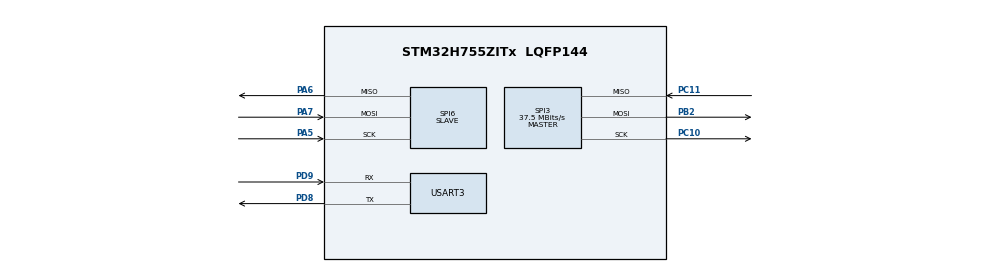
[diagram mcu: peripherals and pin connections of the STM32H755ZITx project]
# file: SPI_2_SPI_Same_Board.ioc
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CORTEX_M7.default_mode_Activation=1
CortexM4.IPs=BDMA,CORTEX_M4\:I,DMA,FATFS_M4\:I,FREERTOS_M4\:I,GPIO,IWDG2\:I,MDMA,NVIC2\:I,OPENAMP_M4\:I,PDM2PCM_M4\:I,PWR,RCC,RESMGR_UTILITY,SYS_M4\:I,USB_DEVICE_M4\:I,USB_HOST_M4\:I,VREFBUF,WWDG2\:I
CortexM7.IPs=BDMA\:I,CORTEX_M7\:I,DMA\:I,FATFS_M7\:I,FREERTOS_M7\:I,GPIO\:I,IWDG1\:I,MDMA\:I,NVIC1\:I,OPENAMP_M7\:I,PDM2PCM_M7\:I,PWR\:I,RCC\:I,RESMGR_UTILITY\:I,SYS\:I,USB_DEVICE_M7\:I,USB_HOST_M7\:I,VREFBUF\:I,WWDG1\:I,SPI3\:I,SPI6\:I,USART3\:I
Mcu.Family=STM32H7
Mcu.Name=STM32H755ZITx
Mcu.Package=LQFP144
NVIC1.PriorityGroup=NVIC_PRIORITYGROUP_4
NVIC2.PriorityGroup=NVIC_PRIORITYGROUP_4
PA5.Mode=Full_Duplex_Slave
PA5.PinAttribute=CortexM7
PA5.Signal=SPI6_SCK
PA6.Mode=Full_Duplex_Slave
PA6.PinAttribute=CortexM7
PA6.Signal=SPI6_MISO
PA7.Mode=Full_Duplex_Slave
PA7.PinAttribute=CortexM7
PA7.Signal=SPI6_MOSI
PB2.Mode=Full_Duplex_Master
PB2.PinAttribute=CortexM7
PB2.Signal=SPI3_MOSI
PC10.Mode=Full_Duplex_Master
PC10.PinAttribute=CortexM7
PC10.Signal=SPI3_SCK
PC11.Mode=Full_Duplex_Master
PC11.PinAttribute=CortexM7
PC11.Signal=SPI3_MISO
PD8.Mode=Asynchronous
PD8.PinAttribute=CortexM7
PD8.Signal=USART3_TX
PD9.Mode=Asynchronous
PD9.PinAttribute=CortexM7
PD9.Signal=USART3_RX
PH0-OSC_IN\ (PH0).Mode=HSE-External-Oscillator
PH0-OSC_IN\ (PH0).PinAttribute=Free
PH0-OSC_IN\ (PH0).Signal=RCC_OSC_IN
PH1-OSC_OUT\ (PH1).Mode=HSE-External-Oscillator
PH1-OSC_OUT\ (PH1).PinAttribute=Free
PH1-OSC_OUT\ (PH1).Signal=RCC_OSC_OUT
ProjectManager.HeapSize=M4-0x200,M7-0x200
ProjectManager.StackSize=M4-0x400,M7-0x400
ProjectManager.TargetToolchain=STM32CubeIDE
RCC.ADCFreq_Value=400000000
RCC.APB1Freq_Value=75000000
RCC.APB2Freq_Value=75000000
RCC.APB3Freq_Value=75000000
RCC.APB4Freq_Value=37500000
RCC.CortexFreq_Value=75000000
RCC.D3PPRE=RCC_APB4_DIV2
RCC.DIVM1=2
RCC.DIVM2=2
RCC.DIVN1=12
RCC.DIVN2=64
RCC.DIVQ2=25
RCC.HCLKFreq_Value=75000000
RCC.PLL2FRACN=0
RCC.PLLFRACN=0
RCC.PLLSourceVirtual=RCC_PLLSOURCE_HSE
RCC.SYSCLKFreq_VALUE=75000000
RCC.SYSCLKSource=RCC_SYSCLKSOURCE_PLLCLK
RCC.USART234578CLockSelection=RCC_USART234578CLKSOURCE_PLL2
RCC.USBFreq_Value=75000000
SPI3.CalculateBaudRate=37.5 MBits/s
SPI3.DataSize=SPI_DATASIZE_8BIT
SPI3.Direction=SPI_DIRECTION_2LINES
SPI3.Mode=SPI_MODE_MASTER
SPI3.VirtualType=VM_MASTER
SPI6.DataSize=SPI_DATASIZE_8BIT
SPI6.Direction=SPI_DIRECTION_2LINES
SPI6.Mode=SPI_MODE_SLAVE
SPI6.VirtualType=VM_SLAVE
SYS.userName=SYS_M7
USART3.VirtualMode-Asynchronous=VM_ASYNC
VP_SYS_M4_VS_Systick.Mode=SysTick
board=custom

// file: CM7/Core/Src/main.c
/* USER CODE BEGIN Header */
/**
  ******************************************************************************
  * @file           : main.c
  * @brief          : Main program body
  ******************************************************************************
  * @attention
  *
  * Copyright (c) 2024 STMicroelectronics.
  * All rights reserved.
  *
  * This software is licensed under terms that can be found in the LICENSE file
  * in the root directory of this software component.
  * If no LICENSE file comes with this software, it is provided AS-IS.
  *
  ******************************************************************************
  */
/* USER CODE END Header */
#include "main.h"
#include "spi.h"
#include "usart.h"
#include "gpio.h"

/* USER CODE BEGIN PD */

#ifndef HSEM_ID_0
#define HSEM_ID_0 (0U) /* HW semaphore 0*/
#endif

/* USER CODE END PD */

void SystemClock_Config(void);
static void MPU_Config(void);

int main(void)
{

/* USER CODE BEGIN Boot_Mode_Sequence_0 */
  int32_t timeout;
/* USER CODE END Boot_Mode_Sequence_0 */

  /* MPU Configuration--------------------------------------------------------*/
  MPU_Config();

/* USER CODE BEGIN Boot_Mode_Sequence_1 */
  /* Wait until CPU2 boots and enters in stop mode or timeout*/
  timeout = 0xFFFF;
  while((__HAL_RCC_GET_FLAG(RCC_FLAG_D2CKRDY) != RESET) && (timeout-- > 0));
  if ( timeout < 0 )
  {
  Error_Handler();
  }
/* USER CODE END Boot_Mode_Sequence_1 */
  /* MCU Configuration--------------------------------------------------------*/

  /* Reset of all peripherals, Initializes the Flash interface and the Systick. */
  HAL_Init();

  /* Configure the system clock */
  SystemClock_Config();
/* USER CODE BEGIN Boot_Mode_Sequence_2 */
/* When system initialization is finished, Cortex-M7 will release Cortex-M4 by means of
HSEM notification */
/*HW semaphore Clock enable*/
__HAL_RCC_HSEM_CLK_ENABLE();
/*Take HSEM */
HAL_HSEM_FastTake(HSEM_ID_0);
/*Release HSEM in order to notify the CPU2(CM4)*/
HAL_HSEM_Release(HSEM_ID_0,0);
/* wait until CPU2 wakes up from stop mode */
timeout = 0xFFFF;
while((__HAL_RCC_GET_FLAG(RCC_FLAG_D2CKRDY) == RESET) && (timeout-- > 0));
if ( timeout < 0 )
{
Error_Handler();
}
/* USER CODE END Boot_Mode_Sequence_2 */

  /* Initialize all configured peripherals */
  MX_GPIO_Init();
  MX_SPI3_Init();
  MX_SPI6_Init();
  MX_USART3_UART_Init();
  /* USER CODE BEGIN 2 */

  // Master sends data
  uint8_t dataToSend = 0x55;
  //HAL_SPI_Transmit(&hspi3, &dataToSend, 1, HAL_MAX_DELAY);

  // Master receives data
  uint8_t dataReceived;
  //HAL_SPI_Receive(&hspi6, &dataReceived, 1, HAL_MAX_DELAY);
  /* USER CODE END 2 */

  /* Infinite loop */
  while (1)
  {

    /* USER CODE BEGIN 3 */
	  HAL_SPI_Transmit(&hspi3, &dataToSend, 1, HAL_MAX_DELAY);
	  HAL_SPI_Receive(&hspi6, &dataReceived, 1, HAL_MAX_DELAY);
	  HAL_UART_Transmit(&huart3, &dataReceived, 1, HAL_MAX_DELAY);
  }
  /* USER CODE END 3 */
}

void SystemClock_Config(void)
{
  RCC_OscInitTypeDef RCC_OscInitStruct = {0};
  RCC_ClkInitTypeDef RCC_ClkInitStruct = {0};

  /** Supply configuration update enable
  */
  HAL_PWREx_ConfigSupply(PWR_DIRECT_SMPS_SUPPLY);

  /** Configure the main internal regulator output voltage
  */
  __HAL_PWR_VOLTAGESCALING_CONFIG(PWR_REGULATOR_VOLTAGE_SCALE3);

  while(!__HAL_PWR_GET_FLAG(PWR_FLAG_VOSRDY)) {}

  /** Initializes the RCC Oscillators according to the specified parameters
  * in the RCC_OscInitTypeDef structure.
  */
  RCC_OscInitStruct.OscillatorType = RCC_OSCILLATORTYPE_HSE;
  RCC_OscInitStruct.HSEState = RCC_HSE_ON;
  RCC_OscInitStruct.PLL.PLLState = RCC_PLL_ON;
  RCC_OscInitStruct.PLL.PLLSource = RCC_PLLSOURCE_HSE;
  RCC_OscInitStruct.PLL.PLLM = 2;
  RCC_OscInitStruct.PLL.PLLN = 12;
  RCC_OscInitStruct.PLL.PLLP = 2;
  RCC_OscInitStruct.PLL.PLLQ = 2;
  RCC_OscInitStruct.PLL.PLLR = 2;
  RCC_OscInitStruct.PLL.PLLRGE = RCC_PLL1VCIRANGE_3;
  RCC_OscInitStruct.PLL.PLLVCOSEL = RCC_PLL1VCOMEDIUM;
  RCC_OscInitStruct.PLL.PLLFRACN = 0;
  if (HAL_RCC_OscConfig(&RCC_OscInitStruct) != HAL_OK)
  {
    Error_Handler();
  }

  /** Initializes the CPU, AHB and APB buses clocks
  */
  RCC_ClkInitStruct.ClockType = RCC_CLOCKTYPE_HCLK|RCC_CLOCKTYPE_SYSCLK
                              |RCC_CLOCKTYPE_PCLK1|RCC_CLOCKTYPE_PCLK2
                              |RCC_CLOCKTYPE_D3PCLK1|RCC_CLOCKTYPE_D1PCLK1;
  RCC_ClkInitStruct.SYSCLKSource = RCC_SYSCLKSOURCE_PLLCLK;
  RCC_ClkInitStruct.SYSCLKDivider = RCC_SYSCLK_DIV1;
  RCC_ClkInitStruct.AHBCLKDivider = RCC_HCLK_DIV1;
  RCC_ClkInitStruct.APB3CLKDivider = RCC_APB3_DIV1;
  RCC_ClkInitStruct.APB1CLKDivider = RCC_APB1_DIV1;
  RCC_ClkInitStruct.APB2CLKDivider = RCC_APB2_DIV1;
  RCC_ClkInitStruct.APB4CLKDivider = RCC_APB4_DIV2;

  if (HAL_RCC_ClockConfig(&RCC_ClkInitStruct, FLASH_LATENCY_1) != HAL_OK)
  {
    Error_Handler();
  }
}

 /* MPU Configuration */

void MPU_Config(void)
{
  MPU_Region_InitTypeDef MPU_InitStruct = {0};

  /* Disables the MPU */
  HAL_MPU_Disable();

  /** Initializes and configures the Region and the memory to be protected
  */
  MPU_InitStruct.Enable = MPU_REGION_ENABLE;
  MPU_InitStruct.Number = MPU_REGION_NUMBER0;
  MPU_InitStruct.BaseAddress = 0x0;
  MPU_InitStruct.Size = MPU_REGION_SIZE_4GB;
  MPU_InitStruct.SubRegionDisable = 0x87;
  MPU_InitStruct.TypeExtField = MPU_TEX_LEVEL0;
  MPU_InitStruct.AccessPermission = MPU_REGION_NO_ACCESS;
  MPU_InitStruct.DisableExec = MPU_INSTRUCTION_ACCESS_DISABLE;
  MPU_InitStruct.IsShareable = MPU_ACCESS_SHAREABLE;
  MPU_InitStruct.IsCacheable = MPU_ACCESS_NOT_CACHEABLE;
  MPU_InitStruct.IsBufferable = MPU_ACCESS_NOT_BUFFERABLE;

  HAL_MPU_ConfigRegion(&MPU_InitStruct);
  /* Enables the MPU */
  HAL_MPU_Enable(MPU_PRIVILEGED_DEFAULT);

}

void Error_Handler(void)
{
  __disable_irq();
  while (1)
  {
  }
}
